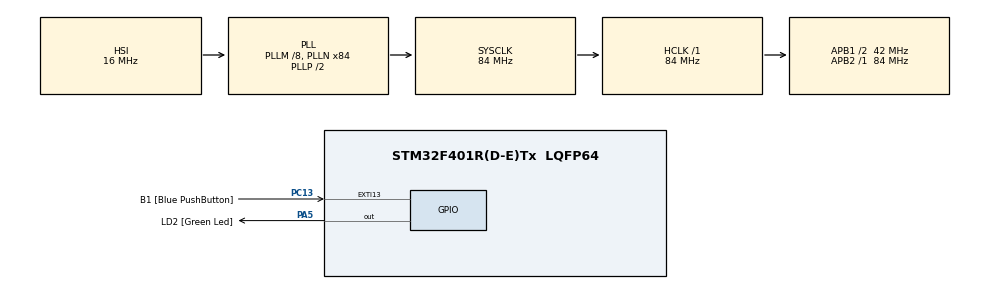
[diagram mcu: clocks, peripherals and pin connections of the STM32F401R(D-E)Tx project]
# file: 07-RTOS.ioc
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Mcu.Family=STM32F4
Mcu.Name=STM32F401R(D-E)Tx
Mcu.Package=LQFP64
NVIC.PriorityGroup=NVIC_PRIORITYGROUP_4
NVIC.TIM1_BRK_TIM9_IRQn=true\:15\:0\:false\:false\:true\:false\:true\:true
NVIC.TimeBase=TIM1_BRK_TIM9_IRQn
NVIC.TimeBaseIP=TIM9
PA13.GPIO_Label=TMS
PA13.Signal=SYS_JTMS-SWDIO
PA14.GPIO_Label=TCK
PA14.Signal=SYS_JTCK-SWCLK
PA2.GPIO_Label=USART_TX
PA2.GPIO_Mode=GPIO_MODE_AF_PP
PA2.GPIO_PuPd=GPIO_NOPULL
PA2.GPIO_Speed=GPIO_SPEED_FREQ_LOW
PA2.Signal=USART2_TX
PA3.GPIO_Label=USART_RX
PA3.GPIO_Mode=GPIO_MODE_AF_PP
PA3.GPIO_PuPd=GPIO_NOPULL
PA3.GPIO_Speed=GPIO_SPEED_FREQ_LOW
PA3.Signal=USART2_RX
PA5.GPIO_Label=LD2 [Green Led]
PA5.GPIO_Mode=GPIO_MODE_OUTPUT_PP
PA5.GPIO_PuPd=GPIO_NOPULL
PA5.GPIO_Speed=GPIO_SPEED_FREQ_LOW
PA5.Signal=GPIO_Output
PB3.GPIO_Label=SWO
PB3.Signal=SYS_JTDO-SWO
PC13-ANTI_TAMP.GPIO_Label=B1 [Blue PushButton]
PC13-ANTI_TAMP.GPIO_ModeDefaultEXTI=GPIO_MODE_IT_FALLING
PC13-ANTI_TAMP.GPIO_PuPd=GPIO_NOPULL
PC13-ANTI_TAMP.Signal=GPXTI13
PC14-OSC32_IN.Signal=RCC_OSC32_IN
PC15-OSC32_OUT.Signal=RCC_OSC32_OUT
PH0\ -\ OSC_IN.Signal=RCC_OSC_IN
PH1\ -\ OSC_OUT.Signal=RCC_OSC_OUT
ProjectManager.HeapSize=0x200
ProjectManager.StackSize=0x400
ProjectManager.TargetToolchain=STM32CubeIDE
RCC.AHBFreq_Value=84000000
RCC.APB1CLKDivider=RCC_HCLK_DIV2
RCC.APB1Freq_Value=42000000
RCC.APB1TimFreq_Value=84000000
RCC.APB2Freq_Value=84000000
RCC.APB2TimFreq_Value=84000000
RCC.CortexFreq_Value=84000000
RCC.HCLKFreq_Value=84000000
RCC.HSE_VALUE=8000000
RCC.HSI_VALUE=16000000
RCC.LSE_VALUE=32768
RCC.PLLN=336
RCC.PLLP=RCC_PLLP_DIV4
RCC.PLLQ=7
RCC.SYSCLKFreq_VALUE=84000000
RCC.SYSCLKSource=RCC_SYSCLKSOURCE_PLLCLK
RCC.VCOOutputFreq_Value=336000000
VP_SYS_VS_tim9.Mode=TIM9
board=NUCLEO-F401RE

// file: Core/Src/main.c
/* USER CODE BEGIN Header */
/**
 ******************************************************************************
 * @file           : main.c
 * @brief          : Main program body - RGB LED Control with FreeRTOS (Simple State Machine)
 ******************************************************************************
 */
/* USER CODE END Header */
#include "main.h"

/* USER CODE BEGIN Includes */
#include "FreeRTOS.h"
#include "task.h"
#include <stdio.h>
/* USER CODE END Includes */

/* USER CODE BEGIN PTD */
// LED state enum
typedef enum
{
  LED_STATE_RED = 0,
  LED_STATE_BLUE,
  LED_STATE_GREEN
} LedState_t;
/* USER CODE END PTD */

/* USER CODE BEGIN PD */
#define STACK_SIZE 128
#define GPIOAEN (1UL << 0) // GPIOA clock enable
#define GPIOCEN (1UL << 2) // GPIOC clock enable

// LED Pins on GPIOA
#define RED_LED_PIN (1UL << 8)    // RED LED on PA8
#define BLUE_LED_PIN (1UL << 9)   // BLUE LED on PA9
#define GREEN_LED_PIN (1UL << 10) // GREEN LED on PA10

// LED states
#define LED_ON 1
#define LED_OFF 0

/* USER CODE END PD */

/* USER CODE BEGIN PV */
// Global variable to track the current LED state
volatile LedState_t currentLedState = LED_STATE_RED;

// Task handles
TaskHandle_t redTaskHandle;
TaskHandle_t blueTaskHandle;
TaskHandle_t greenTaskHandle;
/* USER CODE END PV */

void SystemClock_Config(void);
/* USER CODE BEGIN PFP */
void vRedLedTask(void *pvParameters);   // Task for RED LED
void vBlueLedTask(void *pvParameters);  // Task for BLUE LED
void vGreenLedTask(void *pvParameters); // Task for GREEN LED
void SEGGER_UART_init(uint32_t baud);
void SEGGER_SYSVIEW_Conf(void);
void SEGGER_SYSVIEW_PrintfTarget(const char *fmt, ...);
/* USER CODE END PFP */

/* USER CODE BEGIN 0 */
#define DWT_CTRL (*(volatile uint32_t *)0xE0001000)

// Helper function to control LED - updated with proper ON/OFF control
void controlLed(uint32_t pin, uint8_t state)
{
  if (state == LED_ON)
  {
    GPIOA->BSRR = pin; // Set bit (turn ON LED)
  }
  else
  {
    GPIOA->BSRR = (pin << 16); // Reset bit (turn OFF LED)
  }
}
/* USER CODE END 0 */

int main(void)
{
  /* USER CODE BEGIN 1 */
  BaseType_t status;
  /* USER CODE END 1 */

  /* MCU Configuration--------------------------------------------------------*/

  /* Reset of all peripherals, Initializes the Flash interface and the Systick. */
  HAL_Init();

  /* Configure the system clock */
  SystemClock_Config();

  /* Initialize all configured peripherals */
  /* USER CODE BEGIN 2 */
  // Enable GPIO clocks
  RCC->AHB1ENR |= GPIOAEN | GPIOCEN;

  // Configure PA8, PA9, PA10 (RGB LEDs) as outputs
  GPIOA->MODER &= ~(3UL << (8 * 2)); // Clear mode bits for PA8
  GPIOA->MODER |= (1UL << (8 * 2));  // Set PA8 to output mode (RED)

  GPIOA->MODER &= ~(3UL << (9 * 2)); // Clear mode bits for PA9
  GPIOA->MODER |= (1UL << (9 * 2));  // Set PA9 to output mode (BLUE)

  GPIOA->MODER &= ~(3UL << (10 * 2)); // Clear mode bits for PA10
  GPIOA->MODER |= (1UL << (10 * 2));  // Set PA10 to output mode (GREEN)

  // Configure PC13 (Button) as input with pull-up
  GPIOC->MODER &= ~(3UL << (13 * 2)); // Clear mode bits for pin 13 (input mode = 00)
  GPIOC->PUPDR &= ~(3UL << (13 * 2)); // Clear pull-up/pull-down
  GPIOC->PUPDR |= (1UL << (13 * 2));  // Set to pull-up (01)

  // Ensure all LEDs are OFF initially
  controlLed(RED_LED_PIN, LED_OFF);
  controlLed(BLUE_LED_PIN, LED_OFF);
  controlLed(GREEN_LED_PIN, LED_OFF);

  // Initialize Segger debug
  DWT_CTRL |= (1 << 0);     // Enable DWT
  SEGGER_UART_init(500000); // Initialize SEGGER UART
  SEGGER_SYSVIEW_Conf();    // Initialize SEGGER SystemView

  /* Create the three LED tasks */
  status = xTaskCreate(vRedLedTask, "Task 1", 200, "Hello world task 1 ", 2, &redTaskHandle);
  configASSERT(status == pdPASS);

  status = xTaskCreate(vBlueLedTask, "Task 2", 200, "Hello world task 2 ", 2, &blueTaskHandle);
  configASSERT(status == pdPASS);

  status = xTaskCreate(vGreenLedTask, "Task 3", 200, "Hello world task 3 ", 2, &greenTaskHandle);
  configASSERT(status == pdPASS);

  // Initially suspend the BLUE and GREEN tasks, start with RED only
  vTaskSuspend(blueTaskHandle);
  vTaskSuspend(greenTaskHandle);

  // Start the scheduler
  vTaskStartScheduler();

  /* USER CODE END 2 */

  /* Infinite loop */
  while (1)
  {

    /* USER CODE BEGIN 3 */
    /* Code will never reach here if the scheduler is running */
  }
  /* USER CODE END 3 */
}

void SystemClock_Config(void)
{
  RCC_OscInitTypeDef RCC_OscInitStruct = {0};
  RCC_ClkInitTypeDef RCC_ClkInitStruct = {0};

  /** Configure the main internal regulator output voltage
   */
  __HAL_RCC_PWR_CLK_ENABLE();
  __HAL_PWR_VOLTAGESCALING_CONFIG(PWR_REGULATOR_VOLTAGE_SCALE2);

  /** Initializes the RCC Oscillators according to the specified parameters
   * in the RCC_OscInitTypeDef structure.
   */
  RCC_OscInitStruct.OscillatorType = RCC_OSCILLATORTYPE_HSI;
  RCC_OscInitStruct.HSIState = RCC_HSI_ON;
  RCC_OscInitStruct.HSICalibrationValue = RCC_HSICALIBRATION_DEFAULT;
  RCC_OscInitStruct.PLL.PLLState = RCC_PLL_ON;
  RCC_OscInitStruct.PLL.PLLSource = RCC_PLLSOURCE_HSI;
  RCC_OscInitStruct.PLL.PLLM = 8;
  RCC_OscInitStruct.PLL.PLLN = 84;
  RCC_OscInitStruct.PLL.PLLP = RCC_PLLP_DIV2;
  RCC_OscInitStruct.PLL.PLLQ = 4;
  if (HAL_RCC_OscConfig(&RCC_OscInitStruct) != HAL_OK)
  {
    Error_Handler();
  }

  /** Initializes the CPU, AHB and APB buses clocks
   */
  RCC_ClkInitStruct.ClockType = RCC_CLOCKTYPE_HCLK | RCC_CLOCKTYPE_SYSCLK | RCC_CLOCKTYPE_PCLK1 | RCC_CLOCKTYPE_PCLK2;
  RCC_ClkInitStruct.SYSCLKSource = RCC_SYSCLKSOURCE_PLLCLK;
  RCC_ClkInitStruct.AHBCLKDivider = RCC_SYSCLK_DIV1;
  RCC_ClkInitStruct.APB1CLKDivider = RCC_HCLK_DIV2;
  RCC_ClkInitStruct.APB2CLKDivider = RCC_HCLK_DIV1;

  if (HAL_RCC_ClockConfig(&RCC_ClkInitStruct, FLASH_LATENCY_2) != HAL_OK)
  {
    Error_Handler();
  }
}
/* RED LED Task */
void vRedLedTask(void *pvParameters)
{
  while (1)
  {
    // Turn ON the RED LED
    SEGGER_SYSVIEW_PrintfTarget("RED LED ON - Only RED Task running");
    controlLed(RED_LED_PIN, LED_ON);

    // Keep LED ON for exactly 1 second without using vTaskDelay
    // Instead, keep track of time manually
    TickType_t xStartTime = xTaskGetTickCount();
    while ((xTaskGetTickCount() - xStartTime) < pdMS_TO_TICKS(1000))
    {
      // Do nothing, just wait
    }

    // Turn OFF the RED LED
    controlLed(RED_LED_PIN, LED_OFF);

    // Critical section to ensure atomic operations
    taskENTER_CRITICAL();
    // Resume BLUE task first
    vTaskResume(blueTaskHandle);
    // Then immediately suspend self
    vTaskSuspend(NULL);
    taskEXIT_CRITICAL();
  }
}

/* BLUE LED Task */
void vBlueLedTask(void *pvParameters)
{
  while (1)
  {
    // Turn ON the BLUE LED
    SEGGER_SYSVIEW_PrintfTarget("BLUE LED ON - Only BLUE Task running");
    controlLed(BLUE_LED_PIN, LED_ON);

    // Keep LED ON for exactly 1 second without using vTaskDelay
    TickType_t xStartTime = xTaskGetTickCount();
    while ((xTaskGetTickCount() - xStartTime) < pdMS_TO_TICKS(1000))
    {
      // Do nothing, just wait
    }

    // Turn OFF the BLUE LED
    controlLed(BLUE_LED_PIN, LED_OFF);

    // Critical section to ensure atomic operations
    taskENTER_CRITICAL();
    // Resume GREEN task first
    vTaskResume(greenTaskHandle);
    // Then immediately suspend self
    vTaskSuspend(NULL);
    taskEXIT_CRITICAL();
  }
}

/* GREEN LED Task */
void vGreenLedTask(void *pvParameters)
{
  while (1)
  {
    // Turn ON the GREEN LED
    SEGGER_SYSVIEW_PrintfTarget("GREEN LED ON - Only GREEN Task running");
    controlLed(GREEN_LED_PIN, LED_ON);

    // Keep LED ON for exactly 1 second without using vTaskDelay
    TickType_t xStartTime = xTaskGetTickCount();
    while ((xTaskGetTickCount() - xStartTime) < pdMS_TO_TICKS(1000))
    {
      // Do nothing, just wait
    }

    // Turn OFF the GREEN LED
    controlLed(GREEN_LED_PIN, LED_OFF);

    // Critical section to ensure atomic operations
    taskENTER_CRITICAL();
    // Resume RED task first
    vTaskResume(redTaskHandle);
    // Then immediately suspend self
    vTaskSuspend(NULL);
    taskEXIT_CRITICAL();
  }
}
/* FreeRTOS Hook Functions */
void vApplicationIdleHook(void)
{
  /* This function is called when the idle task is running */
  /* You can add power saving code here */
}

void vApplicationMallocFailedHook(void)
{
  /* This function is called when memory allocation fails */
  /* Handle error here, e.g., restart the system */
  printf("Memory allocation failed!\r\n");
  Error_Handler();
}
/* USER CODE END 4 */

void HAL_TIM_PeriodElapsedCallback(TIM_HandleTypeDef *htim)
{
  if (htim->Instance == TIM9)
  {
    HAL_IncTick();
  }
}

void Error_Handler(void)
{
  __disable_irq();
  while (1)
  {
  }
}
